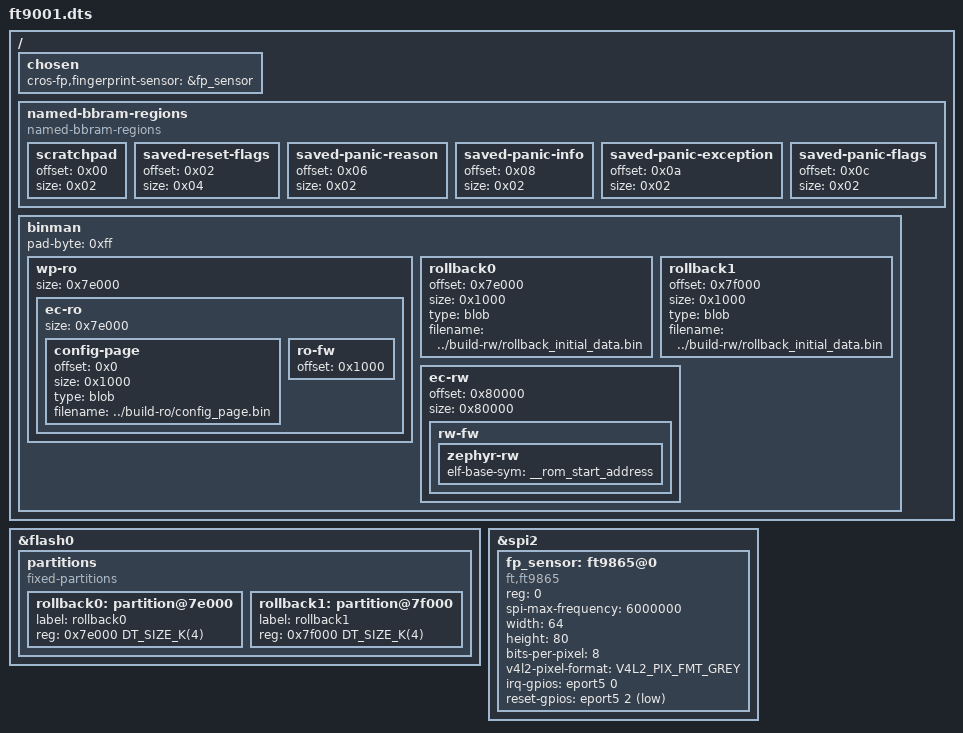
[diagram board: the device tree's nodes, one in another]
/* Copyright 2025 The ChromiumOS Authors.
 * Use of this source code is governed by a BSD-style license that can be
 * found in the LICENSE file.
 */

#include "soc.dtsi"
#include "gpio.dtsi"
#include "rwsig.dtsi"

#include <cros/integrated_fwid.dtsi>

/ {
	chosen {
		cros-fp,fingerprint-sensor = &fp_sensor;
	};

	named-bbram-regions {
		compatible = "named-bbram-regions";

		scratchpad {
			offset = <0x00>;
			size = <0x02>;
		};
		saved-reset-flags {
			offset = <0x02>;
			size = <0x04>;
		};
		saved-panic-reason {
			offset = <0x06>;
			size = <0x02>;
		};
		saved-panic-info {
			offset = <0x08>;
			size = <0x02>;
		};
		saved-panic-exception {
			offset = <0x0a>;
			size = <0x02>;
		};
		saved-panic-flags {
			offset = <0x0c>;
			size = <0x02>;
		};
	};

	binman {
		/* The binary is flashed at 0x1000 offset. The first 0x1000 of flash are for boot data */
		wp-ro {
			size = <0x7e000>;
			ec-ro {
				size = <0x7e000>;
				config-page {
					offset = <0x0>;
					size = <0x1000>;
					type = "blob";
					filename = "../build-ro/config_page.bin";
				};
				ro-fw {
					offset = <0x1000>;
				};
			};
		};

		rollback0 {
			offset = <0x7e000>;
			size = <0x1000>;
			type = "blob";
			filename = "../build-rw/rollback_initial_data.bin";
		};

		rollback1 {
			offset = <0x7f000>;
			size = <0x1000>;
			type = "blob";
			filename = "../build-rw/rollback_initial_data.bin";
		};

		ec-rw {
			offset = <0x80000>;
			size = <0x80000>;
			rw-fw {
				/*
				 * Clang doesn't emit STT_SECTION symbols (also
				 * called 'section symbols'), so 'rom_start'
				 * symbol is not available. Fortunately, Zephyr
				 * linker scripts provide '__rom_start_address'
				 * symbol which points to the beginning of
				 * 'rom_start' section.
				 */
				zephyr-rw {
					elf-base-sym = "__rom_start_address";
				};
			};
		};
		pad-byte = <0xff>;
	};
};

&flash0 {
	partitions {
		compatible = "fixed-partitions";
		#address-cells = <1>;
		#size-cells = <1>;

		rollback0: partition@7e000 {
			label = "rollback0";
			reg = <0x7e000 DT_SIZE_K(4)>;
		};

		rollback1: partition@7f000 {
			label = "rollback1";
			reg = <0x7f000 DT_SIZE_K(4)>;
		};
	};
};

&spi2 {
	fp_sensor: ft9865@0 {
		compatible = "ft,ft9865";
		reg = <0>;
		spi-max-frequency = <6000000>;

		width = <64>;
		height = <80>;
		bits-per-pixel = <8>;
		v4l2-pixel-format = "V4L2_PIX_FMT_GREY";

		irq-gpios = <&eport5 0 (GPIO_ACTIVE_HIGH | GPIO_PULL_DOWN)>;
		reset-gpios = <&eport5 2 GPIO_ACTIVE_LOW>;
	};
};
